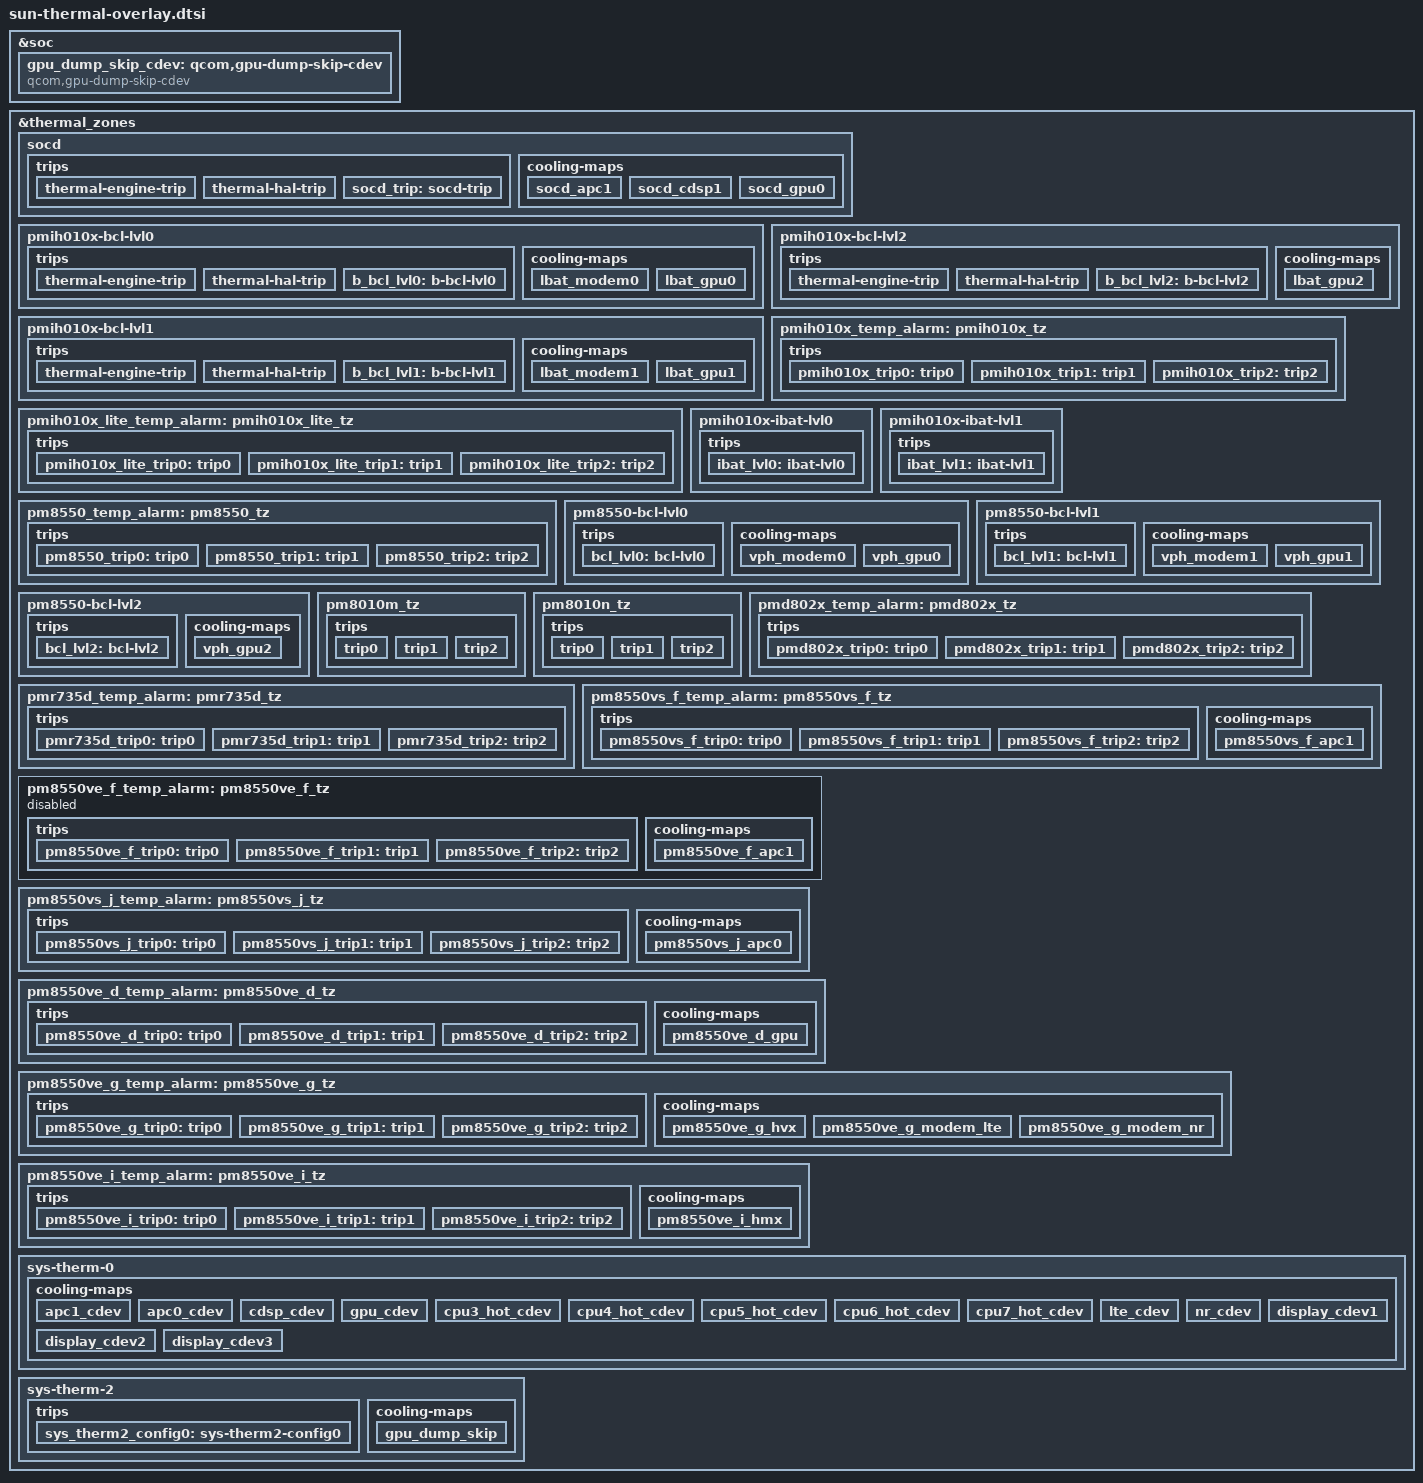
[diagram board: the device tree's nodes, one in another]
// SPDX-License-Identifier: BSD-3-Clause
/*
 * Copyright (c) 2024 Qualcomm Innovation Center, Inc. All rights reserved.
 */

#include <dt-bindings/thermal/thermal_qti.h>

&soc {
	gpu_dump_skip_cdev: qcom,gpu-dump-skip-cdev {
		compatible = "qcom,gpu-dump-skip-cdev";
		nvmem-cells = <&wr_thermal_flag>;
		nvmem-cell-names = "wr_thermal_flag";
		#cooling-cells = <2>;
	};
};

&thermal_zones {
	socd {
		polling-delay-passive = <100>;
		polling-delay = <0>;
		thermal-sensors = <&bcl_soc>;

		trips {
			thermal-engine-trip {
				temperature = <100>;
				hysteresis = <0>;
				type = "passive";
			};

			thermal-hal-trip {
				temperature = <100>;
				hysteresis = <0>;
				type = "passive";
			};

			socd_trip: socd-trip {
				temperature = <90>;
				hysteresis = <0>;
				type = "passive";
			};
		};

		cooling-maps {
			socd_apc1 {
				trip = <&socd_trip>;
				cooling-device = <&APC1_MX_CX_PAUSE 1 1>;
			};

			socd_cdsp1 {
				trip = <&socd_trip>;
				cooling-device = <&cdsp_sw 4 4>;
			};

			socd_gpu0 {
				trip = <&socd_trip>;
				cooling-device = <&msm_gpu 4 4>;
			};
		};
	};

	pmih010x-bcl-lvl0 {
		polling-delay-passive = <100>;
		polling-delay = <0>;
		thermal-sensors = <&pmih010x_bcl 5>;

		trips {
			thermal-engine-trip {
				temperature = <100>;
				hysteresis = <0>;
				type = "passive";
			};

			thermal-hal-trip {
				temperature = <100>;
				hysteresis = <0>;
				type = "passive";
			};

			b_bcl_lvl0: b-bcl-lvl0 {
				temperature = <1>;
				hysteresis = <1>;
				type = "passive";
			};
		};

		cooling-maps {
			lbat_modem0 {
				trip = <&b_bcl_lvl0>;
				cooling-device = <&modem_bcl 1 1>;
			};

			lbat_gpu0 {
				trip = <&b_bcl_lvl0>;
				cooling-device = <&msm_gpu 1 1>;
			};
		};
	};

	pmih010x-bcl-lvl1 {
		polling-delay-passive = <100>;
		polling-delay = <0>;
		thermal-sensors = <&pmih010x_bcl 6>;

		trips {
			thermal-engine-trip {
				temperature = <100>;
				hysteresis = <0>;
				type = "passive";
			};

			thermal-hal-trip {
				temperature = <100>;
				hysteresis = <0>;
				type = "passive";
			};

			b_bcl_lvl1: b-bcl-lvl1 {
				temperature = <1>;
				hysteresis = <1>;
				type = "passive";
			};
		};

		cooling-maps {
			lbat_modem1 {
				trip = <&b_bcl_lvl1>;
				cooling-device = <&modem_bcl 2 2>;
			};

			lbat_gpu1 {
				trip = <&b_bcl_lvl1>;
				cooling-device = <&msm_gpu 2 2>;
			};
		};
	};

	pmih010x-bcl-lvl2 {
		polling-delay-passive = <100>;
		polling-delay = <0>;
		thermal-sensors = <&pmih010x_bcl 7>;

		trips {
			thermal-engine-trip {
				temperature = <100>;
				hysteresis = <0>;
				type = "passive";
			};

			thermal-hal-trip {
				temperature = <100>;
				hysteresis = <0>;
				type = "passive";
			};

			b_bcl_lvl2: b-bcl-lvl2 {
				temperature = <1>;
				hysteresis = <1>;
				type = "passive";
			};
		};

		cooling-maps {
			lbat_gpu2 {
				trip = <&b_bcl_lvl2>;
				cooling-device = <&msm_gpu 3 3>;
			};
		};
	};

	pmih010x_temp_alarm: pmih010x_tz {
		polling-delay-passive = <100>;
		polling-delay = <0>;
		thermal-governor = "step_wise";
		thermal-sensors = <&pmih010x_tz>;

		trips {
			pmih010x_trip0: trip0 {
				temperature = <95000>;
				hysteresis = <0>;
				type = "passive";
			};

			pmih010x_trip1: trip1 {
				temperature = <115000>;
				hysteresis = <0>;
				type = "hot";
			};

			pmih010x_trip2: trip2 {
				temperature = <145000>;
				hysteresis = <0>;
				type = "critical";
			};
		};
	};

	pmih010x_lite_temp_alarm: pmih010x_lite_tz {
		polling-delay-passive = <100>;
		polling-delay = <0>;
		thermal-governor = "step_wise";
		thermal-sensors = <&pmih010x_lite_tz>;

		trips {
			pmih010x_lite_trip0: trip0 {
				temperature = <125000>;
				hysteresis = <0>;
				type = "passive";
			};

			pmih010x_lite_trip1: trip1 {
				temperature = <135000>;
				hysteresis = <0>;
				type = "hot";
			};

			pmih010x_lite_trip2: trip2 {
				temperature = <145000>;
				hysteresis = <0>;
				type = "critical";
			};
		};
	};

	pmih010x-ibat-lvl0 {
		polling-delay-passive = <0>;
		polling-delay = <0>;
		thermal-sensors = <&pmih010x_bcl 0>;

		trips {
			ibat_lvl0:ibat-lvl0 {
				temperature = <13500>;
				hysteresis = <200>;
				type = "passive";
			};
		};
	};

	pmih010x-ibat-lvl1 {
		polling-delay-passive = <0>;
		polling-delay = <0>;
		thermal-sensors = <&pmih010x_bcl 1>;

		trips {
			ibat_lvl1:ibat-lvl1 {
				temperature = <15000>;
				hysteresis = <200>;
				type = "passive";
			};
		};
	};

	pm8550_temp_alarm: pm8550_tz {
		polling-delay-passive = <100>;
		polling-delay = <0>;
		thermal-governor = "step_wise";
		thermal-sensors = <&pm8550_tz>;

		trips {
			pm8550_trip0: trip0 {
				temperature = <95000>;
				hysteresis = <0>;
				type = "passive";
			};

			pm8550_trip1: trip1 {
				temperature = <115000>;
				hysteresis = <0>;
				type = "hot";
			};

			pm8550_trip2: trip2 {
				temperature = <145000>;
				hysteresis = <0>;
				type = "critical";
			};
		};
	};

	pm8550-bcl-lvl0 {
		polling-delay-passive = <100>;
		polling-delay = <0>;
		thermal-governor = "step_wise";
		thermal-sensors = <&pm8550_bcl 5>;

		trips {
			bcl_lvl0: bcl-lvl0 {
				temperature = <1>;
				hysteresis = <1>;
				type = "passive";
			};
		};

		cooling-maps {
			vph_modem0 {
				trip = <&bcl_lvl0>;
				cooling-device = <&modem_bcl 1 1>;
			};

			vph_gpu0 {
				trip = <&bcl_lvl0>;
				cooling-device = <&msm_gpu 1 1>;
			};
		};
	};

	pm8550-bcl-lvl1 {
		polling-delay-passive = <100>;
		polling-delay = <0>;
		thermal-governor = "step_wise";
		thermal-sensors = <&pm8550_bcl 6>;

		trips {
			bcl_lvl1: bcl-lvl1 {
				temperature = <1>;
				hysteresis = <1>;
				type = "passive";
			};
		};

		cooling-maps {
			vph_modem1 {
				trip = <&bcl_lvl1>;
				cooling-device = <&modem_bcl 2 2>;
			};

			vph_gpu1 {
				trip = <&bcl_lvl1>;
				cooling-device = <&msm_gpu 2 2>;
			};
		};
	};

	pm8550-bcl-lvl2 {
		polling-delay-passive = <100>;
		polling-delay = <0>;
		thermal-governor = "step_wise";
		thermal-sensors = <&pm8550_bcl 7>;

		trips {
			bcl_lvl2: bcl-lvl2 {
				temperature = <1>;
				hysteresis = <1>;
				type = "passive";
			};
		};

		cooling-maps {
			vph_gpu2 {
				trip = <&bcl_lvl2>;
				cooling-device = <&msm_gpu 3 3>;
			};
		};
	};

	pm8010m_tz {
		polling-delay-passive = <100>;
		polling-delay = <0>;
		thermal-governor = "step_wise";
		thermal-sensors = <&pm8010m_tz>;

		trips {
			trip0 {
				temperature = <95000>;
				hysteresis = <0>;
				type = "passive";
			};

			trip1 {
				temperature = <115000>;
				hysteresis = <0>;
				type = "hot";
			};

			trip2 {
				temperature = <145000>;
				hysteresis = <0>;
				type = "critical";
			};
		};
	};

	pm8010n_tz {
		polling-delay-passive = <100>;
		polling-delay = <0>;
		thermal-governor = "step_wise";
		thermal-sensors = <&pm8010n_tz>;

		trips {
			trip0 {
				temperature = <95000>;
				hysteresis = <0>;
				type = "passive";
			};

			trip1 {
				temperature = <115000>;
				hysteresis = <0>;
				type = "hot";
			};

			trip2 {
				temperature = <145000>;
				hysteresis = <0>;
				type = "critical";
			};
		};
	};

	pmd802x_temp_alarm: pmd802x_tz {
		polling-delay-passive = <100>;
		polling-delay = <0>;
		thermal-governor = "step_wise";
		thermal-sensors = <&pmd802x_tz>;

		trips {
			pmd802x_trip0: trip0 {
				temperature = <95000>;
				hysteresis = <0>;
				type = "passive";
			};

			pmd802x_trip1: trip1 {
				temperature = <115000>;
				hysteresis = <0>;
				type = "hot";
			};

			pmd802x_trip2: trip2 {
				temperature = <145000>;
				hysteresis = <0>;
				type = "critical";
			};
		};
	};

	pmr735d_temp_alarm: pmr735d_tz {
		polling-delay-passive = <100>;
		polling-delay = <0>;
		thermal-governor = "step_wise";
		thermal-sensors = <&pmr735d_tz>;

		trips {
			pmr735d_trip0: trip0 {
				temperature = <95000>;
				hysteresis = <0>;
				type = "passive";
			};

			pmr735d_trip1: trip1 {
				temperature = <115000>;
				hysteresis = <0>;
				type = "hot";
			};

			pmr735d_trip2: trip2 {
				temperature = <145000>;
				hysteresis = <0>;
				type = "critical";
			};
		};
	};

	/* v6 board */
	pm8550vs_f_temp_alarm: pm8550vs_f_tz {
		polling-delay-passive = <100>;
		polling-delay = <0>;
		thermal-governor = "step_wise";
		thermal-sensors = <&pm8550vs_f_tz>;

		trips {
			pm8550vs_f_trip0: trip0 {
				temperature = <95000>;
				hysteresis = <0>;
				type = "passive";
			};

			pm8550vs_f_trip1: trip1 {
				temperature = <115000>;
				hysteresis = <0>;
				type = "hot";
			};

			pm8550vs_f_trip2: trip2 {
				temperature = <145000>;
				hysteresis = <0>;
				type = "critical";
			};
		};

		cooling-maps {
			pm8550vs_f_apc1 {
				trip = <&pm8550vs_f_trip0>;
				cooling-device = <&APC1_MX_CX_PAUSE 1 1>;
			};
		};
	};

	/* v8 board */
	pm8550ve_f_temp_alarm: pm8550ve_f_tz {
		polling-delay-passive = <100>;
		polling-delay = <0>;
		thermal-governor = "step_wise";
		thermal-sensors = <&pm8550ve_f_tz>;
		status = "disabled";

		trips {
			pm8550ve_f_trip0: trip0 {
				temperature = <95000>;
				hysteresis = <0>;
				type = "passive";
			};

			pm8550ve_f_trip1: trip1 {
				temperature = <115000>;
				hysteresis = <0>;
				type = "hot";
			};

			pm8550ve_f_trip2: trip2 {
				temperature = <145000>;
				hysteresis = <0>;
				type = "critical";
			};
		};

		cooling-maps {
			pm8550ve_f_apc1 {
				trip = <&pm8550ve_f_trip0>;
				cooling-device = <&APC1_MX_CX_PAUSE 1 1>;
			};
		};
	};

	pm8550vs_j_temp_alarm: pm8550vs_j_tz {
		polling-delay-passive = <100>;
		polling-delay = <0>;
		thermal-governor = "step_wise";
		thermal-sensors = <&pm8550vs_j_tz>;

		trips {
			pm8550vs_j_trip0: trip0 {
				temperature = <95000>;
				hysteresis = <0>;
				type = "passive";
			};

			pm8550vs_j_trip1: trip1 {
				temperature = <115000>;
				hysteresis = <0>;
				type = "hot";
			};

			pm8550vs_j_trip2: trip2 {
				temperature = <145000>;
				hysteresis = <0>;
				type = "critical";
			};
		};

		cooling-maps {
			pm8550vs_j_apc0 {
				trip = <&pm8550vs_j_trip0>;
				cooling-device = <&APC0_MX_CX_PAUSE 1 1>;
			};
		};
	};

	pm8550ve_d_temp_alarm: pm8550ve_d_tz {
		polling-delay-passive = <100>;
		polling-delay = <0>;
		thermal-governor = "step_wise";
		thermal-sensors = <&pm8550ve_d_tz>;

		trips {
			pm8550ve_d_trip0: trip0 {
				temperature = <95000>;
				hysteresis = <0>;
				type = "passive";
			};

			pm8550ve_d_trip1: trip1 {
				temperature = <115000>;
				hysteresis = <0>;
				type = "hot";
			};

			pm8550ve_d_trip2: trip2 {
				temperature = <145000>;
				hysteresis = <0>;
				type = "critical";
			};
		};

		cooling-maps {
			pm8550ve_d_gpu {
				trip = <&pm8550ve_d_trip0>;
				cooling-device = <&msm_gpu 5 THERMAL_NO_LIMIT>;
			};
		};
	};

	pm8550ve_g_temp_alarm: pm8550ve_g_tz {
		polling-delay-passive = <100>;
		polling-delay = <0>;
		thermal-governor = "step_wise";
		thermal-sensors = <&pm8550ve_g_tz>;

		trips {
			pm8550ve_g_trip0: trip0 {
				temperature = <95000>;
				hysteresis = <0>;
				type = "passive";
			};

			pm8550ve_g_trip1: trip1 {
				temperature = <115000>;
				hysteresis = <0>;
				type = "hot";
			};

			pm8550ve_g_trip2: trip2 {
				temperature = <145000>;
				hysteresis = <0>;
				type = "critical";
			};
		};

		cooling-maps {
			pm8550ve_g_hvx {
				trip = <&pm8550ve_g_trip0>;
				cooling-device = <&cdsp_sw_hvx 5 THERMAL_NO_LIMIT>;
			};

			pm8550ve_g_modem_lte {
				trip = <&pm8550ve_g_trip0>;
				cooling-device = <&modem_lte_dsc 255 255>;
			};

			pm8550ve_g_modem_nr {
				trip = <&pm8550ve_g_trip0>;
				cooling-device = <&modem_nr_dsc 255 255>;
			};
		};
	};

	pm8550ve_i_temp_alarm: pm8550ve_i_tz {
		polling-delay-passive = <100>;
		polling-delay = <0>;
		thermal-governor = "step_wise";
		thermal-sensors = <&pm8550ve_i_tz>;

		trips {
			pm8550ve_i_trip0: trip0 {
				temperature = <95000>;
				hysteresis = <0>;
				type = "passive";
			};

			pm8550ve_i_trip1: trip1 {
				temperature = <115000>;
				hysteresis = <0>;
				type = "hot";
			};

			pm8550ve_i_trip2: trip2 {
				temperature = <145000>;
				hysteresis = <0>;
				type = "critical";
			};
		};

		cooling-maps {
			pm8550ve_i_hmx {
				trip = <&pm8550ve_i_trip0>;
				cooling-device = <&cdsp_sw_hmx 5 THERMAL_NO_LIMIT>;
			};
		};
	};

	sys-therm-0 {
		cooling-maps {
			apc1_cdev {
				trip = <&trip_config0>;
				cooling-device = <&APC1_MX_CX_PAUSE 1 1>;
			};

			apc0_cdev {
				trip = <&trip_config0>;
				cooling-device = <&APC0_MX_CX_PAUSE 1 1>;
			};

			cdsp_cdev {
				trip = <&trip_config0>;
				cooling-device = <&cdsp_sw 5 THERMAL_NO_LIMIT>;
			};

			gpu_cdev {
				trip = <&trip_config0>;
				cooling-device = <&msm_gpu 5 THERMAL_NO_LIMIT>;
			};

			cpu3_hot_cdev {
				trip = <&trip_config1>;
				cooling-device = <&cpu3_hotplug 1 1>;
			};

			cpu4_hot_cdev {
				trip = <&trip_config1>;
				cooling-device = <&cpu4_hotplug 1 1>;
			};

			cpu5_hot_cdev {
				trip = <&trip_config1>;
				cooling-device = <&cpu5_hotplug 1 1>;
			};

			cpu6_hot_cdev {
				trip = <&trip_config1>;
				cooling-device = <&cpu6_hotplug 1 1>;
			};

			cpu7_hot_cdev {
				trip = <&trip_config1>;
				cooling-device = <&cpu7_hotplug 1 1>;
			};

			lte_cdev {
				trip = <&trip_config1>;
				cooling-device = <&modem_lte_dsc 255 255>;
			};

			nr_cdev {
				trip = <&trip_config1>;
				cooling-device = <&modem_nr_scg_dsc 255 255>;
			};

			display_cdev1 {
				trip = <&display_test_config1>;
				cooling-device = <&display_fps 1 1>;
			};

			display_cdev2 {
				trip = <&display_test_config2>;
				cooling-device = <&display_fps 2 2>;
			};

			display_cdev3 {
				trip = <&display_test_config3>;
				cooling-device = <&display_fps 3 3>;
			};
		};
	};

	sys-therm-2 {
		trips {
			sys_therm2_config0: sys-therm2-config0 {
				temperature = <60000>;
				hysteresis = <10000>;
				type = "passive";
			};
		};

		cooling-maps {
			gpu_dump_skip {
				trip = <&sys_therm2_config0>;
				cooling-device = <&gpu_dump_skip_cdev 1 1>;
			};
		};
	};
};
